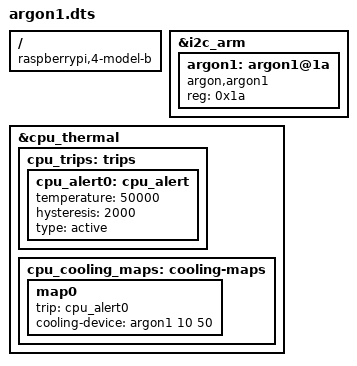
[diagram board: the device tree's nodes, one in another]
/dts-v1/;
/plugin/;

/ {
	compatible = "raspberrypi,4-model-b", "brcm,bcm2711";

	fragment@0 {
		target = <&i2c_arm>;
		__overlay__ {
			#address-cells = <1>;
			#size-cells = <0>;
			status = "okay";

			argon1: argon1@1a {
				compatible = "argon,argon1";
				reg = <0x1a>;
				status = "okay";
				#cooling-cells = <0x02>;
			};
		};
	};

	fragment@1 {
		target = <&cpu_thermal>;
		polling-delay = <2000>;
		__overlay__ {
			cpu_trips: trips {
				cpu_alert0: cpu_alert {
					temperature = <50000>;
					hysteresis = <2000>;
					type = "active";
				};
			};
			cpu_cooling_maps: cooling-maps {
				map0 {
					trip = <&cpu_alert0>;
					cooling-device = <&argon1 10 50>;
				};
			};
		};
	};
};
